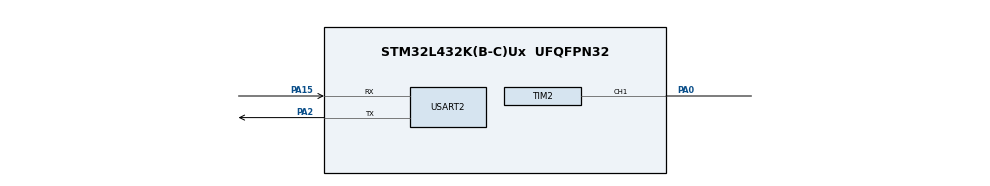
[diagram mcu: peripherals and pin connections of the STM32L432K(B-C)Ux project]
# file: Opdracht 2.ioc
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Mcu.Family=STM32L4
Mcu.Name=STM32L432K(B-C)Ux
Mcu.Package=UFQFPN32
NVIC.PriorityGroup=NVIC_PRIORITYGROUP_4
NVIC.TIM2_IRQn=true\:0\:0\:false\:false\:true\:true\:true\:true
NVIC.USART2_IRQn=true\:0\:0\:false\:false\:true\:true\:true\:true
PA0.GPIO_PuPd=GPIO_NOPULL
PA0.Signal=S_TIM2_CH1
PA15.Mode=Asynchronous
PA15.Signal=USART2_RX
PA13\ (JTMS-SWDIO).Mode=Serial_Wire
PA13\ (JTMS-SWDIO).Signal=SYS_JTMS-SWDIO
PA14\ (JTCK-SWCLK).Mode=Serial_Wire
PA14\ (JTCK-SWCLK).Signal=SYS_JTCK-SWCLK
PA2.Mode=Asynchronous
PA2.Signal=USART2_TX
ProjectManager.HeapSize=0x200
ProjectManager.StackSize=0x400
ProjectManager.TargetToolchain=MDK-ARM V5.32
RCC.HSE_VALUE=8000000
RCC.HSI48_VALUE=48000000
RCC.HSI_VALUE=16000000
RCC.LSE_VALUE=32768
RCC.MSI_VALUE=4000000
RCC.VCOOutputFreq_Value=32000000
SH.S_TIM2_CH1.0=TIM2_CH1,PWM Input on CH1
TIM2.Channel-PWM\ Input\ on\ CH1=TIM_CHANNEL_1
TIM2.Period=3699
TIM2.Prescaler=15
USART2.VirtualMode-Asynchronous=VM_ASYNC
board=custom

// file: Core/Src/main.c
/* USER CODE BEGIN Header */
/**
  ******************************************************************************
  * @file           : main.c
  * @brief          : Main program body
  ******************************************************************************
  * @attention
  *
  * Copyright (c) 2026 STMicroelectronics.
  * All rights reserved.
  *
  * This software is licensed under terms that can be found in the LICENSE file
  * in the root directory of this software component.
  * If no LICENSE file comes with this software, it is provided AS-IS.
  *
  ******************************************************************************
  */
/* USER CODE END Header */
#include "main.h"

/* USER CODE BEGIN Includes */

#include <stdio.h>

/* USER CODE END Includes */

/* USER CODE BEGIN PD */

#define RC5_HALF_MIN_US        640U
#define RC5_HALF_MAX_US        1140U
#define RC5_FULL_MIN_US        1340U
#define RC5_FULL_MAX_US        2220U
#define RC5_FRAME_BITS         14U
#define RC5_FRAME_HALFBITS     (RC5_FRAME_BITS * 2U)
#define RC5_BUFFER_HALFBITS    64U
/* Timing windows used to classify measured pulse widths into RC5 half/full bit times. */

/* USER CODE END PD */

TIM_HandleTypeDef htim2;

UART_HandleTypeDef huart2;

/* USER CODE BEGIN PV */

typedef struct
{
  uint16_t Raw;
  uint8_t StartBit;
  uint8_t FieldBit;
  uint8_t ToggleBit;
  uint8_t Address;
  uint8_t Command;
} IR_Frame_t;

volatile uint8_t RC5FrameReceived = RESET;
IR_Frame_t IR_FRAME;

static uint8_t rc5Collecting = 0U;
static uint8_t rc5HalfBits[RC5_BUFFER_HALFBITS];
static uint8_t rc5HalfCount = 0U;
/* Halfbit buffer stores logic levels after quantization for Manchester decoding. */

/* USER CODE END PV */

void SystemClock_Config(void);
static void MX_GPIO_Init(void);
static void MX_TIM2_Init(void);
static void MX_USART2_UART_Init(void);
/* USER CODE BEGIN PFP */

static void RC5_ResetState(void);
static uint8_t RC5_QuantizeHalfBits(uint32_t durationUs);
static void RC5_AppendLevel(uint8_t level, uint8_t count);
static void RC5_TryDecodeBuffer(void);
static void RC5_ProcessCapture(uint32_t periodUs, uint32_t lowUs);

/* USER CODE END PFP */

int main(void)
{

  /* MCU Configuration--------------------------------------------------------*/

  /* Reset of all peripherals, Initializes the Flash interface and the Systick. */
  HAL_Init();

  /* Configure the system clock */
  SystemClock_Config();

  /* Initialize all configured peripherals */
  MX_GPIO_Init();
  MX_TIM2_Init();
  MX_USART2_UART_Init();
  /* USER CODE BEGIN 2 */

  setvbuf(stdout, NULL, _IONBF, 0);

  RC5_ResetState();

  /* CH1 and CH2 captures are both needed: total period and low-time measurement. */
  if (HAL_TIM_IC_Start_IT(&htim2, TIM_CHANNEL_1) != HAL_OK)
  {
    Error_Handler();
  }
  if (HAL_TIM_IC_Start_IT(&htim2, TIM_CHANNEL_2) != HAL_OK)
  {
    Error_Handler();
  }
  if (HAL_TIM_Base_Start_IT(&htim2) != HAL_OK)
  {
    Error_Handler();
  }

  printf("RC5 receiver ready\r\n");

  /* USER CODE END 2 */

  /* Infinite loop */
  while (1)
  {

    /* USER CODE BEGIN 3 */
    /* Main loop only formats already-decoded data; decode work is done in interrupts. */
    if (RC5FrameReceived != RESET)
    {
      printf("[RC5] Raw: 0x%04X | Addr: 0x%02X | Cmd: 0x%02X | Toggle: %d\r\n",
             IR_FRAME.Raw,
             IR_FRAME.Address,
             IR_FRAME.Command,
             IR_FRAME.ToggleBit);
      RC5FrameReceived = RESET;
    }
  }
  /* USER CODE END 3 */
}

void SystemClock_Config(void)
{
  RCC_OscInitTypeDef RCC_OscInitStruct = {0};
  RCC_ClkInitTypeDef RCC_ClkInitStruct = {0};

  /** Configure the main internal regulator output voltage
  */
  if (HAL_PWREx_ControlVoltageScaling(PWR_REGULATOR_VOLTAGE_SCALE1) != HAL_OK)
  {
    Error_Handler();
  }

  /** Initializes the RCC Oscillators according to the specified parameters
  * in the RCC_OscInitTypeDef structure.
  */
  RCC_OscInitStruct.OscillatorType = RCC_OSCILLATORTYPE_MSI;
  RCC_OscInitStruct.MSIState = RCC_MSI_ON;
  RCC_OscInitStruct.MSICalibrationValue = 0;
  RCC_OscInitStruct.MSIClockRange = RCC_MSIRANGE_6;
  RCC_OscInitStruct.PLL.PLLState = RCC_PLL_NONE;
  if (HAL_RCC_OscConfig(&RCC_OscInitStruct) != HAL_OK)
  {
    Error_Handler();
  }

  /** Initializes the CPU, AHB and APB buses clocks
  */
  RCC_ClkInitStruct.ClockType = RCC_CLOCKTYPE_HCLK|RCC_CLOCKTYPE_SYSCLK
                              |RCC_CLOCKTYPE_PCLK1|RCC_CLOCKTYPE_PCLK2;
  RCC_ClkInitStruct.SYSCLKSource = RCC_SYSCLKSOURCE_MSI;
  RCC_ClkInitStruct.AHBCLKDivider = RCC_SYSCLK_DIV1;
  RCC_ClkInitStruct.APB1CLKDivider = RCC_HCLK_DIV1;
  RCC_ClkInitStruct.APB2CLKDivider = RCC_HCLK_DIV1;

  if (HAL_RCC_ClockConfig(&RCC_ClkInitStruct, FLASH_LATENCY_0) != HAL_OK)
  {
    Error_Handler();
  }
}

static void MX_TIM2_Init(void)
{

  TIM_SlaveConfigTypeDef sSlaveConfig = {0};
  TIM_MasterConfigTypeDef sMasterConfig = {0};
  TIM_IC_InitTypeDef sConfigIC = {0};

  htim2.Instance = TIM2;
  htim2.Init.Prescaler = 15;
  htim2.Init.CounterMode = TIM_COUNTERMODE_UP;
  htim2.Init.Period = 3699;
  htim2.Init.ClockDivision = TIM_CLOCKDIVISION_DIV1;
  htim2.Init.AutoReloadPreload = TIM_AUTORELOAD_PRELOAD_DISABLE;
  if (HAL_TIM_IC_Init(&htim2) != HAL_OK)
  {
    Error_Handler();
  }
  /* Reset mode: each selected trigger edge restarts the timer, giving segment timing. */
  sSlaveConfig.SlaveMode = TIM_SLAVEMODE_RESET;
  sSlaveConfig.InputTrigger = TIM_TS_TI1FP1;
  sSlaveConfig.TriggerPolarity = TIM_TRIGGERPOLARITY_FALLING;
  sSlaveConfig.TriggerFilter = 3;
  if (HAL_TIM_SlaveConfigSynchro(&htim2, &sSlaveConfig) != HAL_OK)
  {
    Error_Handler();
  }
  sMasterConfig.MasterOutputTrigger = TIM_TRGO_RESET;
  sMasterConfig.MasterSlaveMode = TIM_MASTERSLAVEMODE_DISABLE;
  if (HAL_TIMEx_MasterConfigSynchronization(&htim2, &sMasterConfig) != HAL_OK)
  {
    Error_Handler();
  }
  sConfigIC.ICPolarity = TIM_INPUTCHANNELPOLARITY_FALLING;
  sConfigIC.ICSelection = TIM_ICSELECTION_DIRECTTI;
  sConfigIC.ICPrescaler = TIM_ICPSC_DIV1;
  sConfigIC.ICFilter = 3;
  if (HAL_TIM_IC_ConfigChannel(&htim2, &sConfigIC, TIM_CHANNEL_1) != HAL_OK)
  {
    Error_Handler();
  }
  sConfigIC.ICPolarity = TIM_INPUTCHANNELPOLARITY_RISING;
  sConfigIC.ICSelection = TIM_ICSELECTION_INDIRECTTI;
  if (HAL_TIM_IC_ConfigChannel(&htim2, &sConfigIC, TIM_CHANNEL_2) != HAL_OK)
  {
    Error_Handler();
  }

}

static void MX_USART2_UART_Init(void)
{

  huart2.Instance = USART2;
  huart2.Init.BaudRate = 115200;
  huart2.Init.WordLength = UART_WORDLENGTH_8B;
  huart2.Init.StopBits = UART_STOPBITS_1;
  huart2.Init.Parity = UART_PARITY_NONE;
  huart2.Init.Mode = UART_MODE_TX_RX;
  huart2.Init.HwFlowCtl = UART_HWCONTROL_NONE;
  huart2.Init.OverSampling = UART_OVERSAMPLING_16;
  huart2.Init.OneBitSampling = UART_ONE_BIT_SAMPLE_DISABLE;
  huart2.AdvancedInit.AdvFeatureInit = UART_ADVFEATURE_NO_INIT;
  if (HAL_UART_Init(&huart2) != HAL_OK)
  {
    Error_Handler();
  }

}

static void MX_GPIO_Init(void)
{

  /* GPIO Ports Clock Enable */
  __HAL_RCC_GPIOA_CLK_ENABLE();

}

/* USER CODE BEGIN 4 */

int __io_putchar(int ch)
{
  /* Retarget printf single-character output to USART2. */
  HAL_UART_Transmit(&huart2, (uint8_t *)&ch, 1U, 100U);
  return ch;
}

int _write(int file, char *ptr, int len)
{
  (void)file;
  /* Retarget libc buffered writes (printf strings) to USART2. */
  HAL_UART_Transmit(&huart2, (uint8_t *)ptr, (uint16_t)len, HAL_MAX_DELAY);
  return len;
}

void HAL_TIM_IC_CaptureCallback(TIM_HandleTypeDef *htim)
{
  if ((htim->Instance == TIM2) && (htim->Channel == HAL_TIM_ACTIVE_CHANNEL_1))
  {
    /* CH1 captures segment period, CH2 captures low portion of the same segment. */
    uint32_t periodUs = HAL_TIM_ReadCapturedValue(htim, TIM_CHANNEL_1);
    uint32_t lowUs = HAL_TIM_ReadCapturedValue(htim, TIM_CHANNEL_2);
    RC5_ProcessCapture(periodUs, lowUs);
  }
}

void HAL_TIM_PeriodElapsedCallback(TIM_HandleTypeDef *htim)
{
  if (htim->Instance == TIM2)
  {
    /* Timeout means stream likely ended; clear partial decode state. */
    if (RC5FrameReceived == RESET)
    {
      RC5_ResetState();
    }
  }
}

static void RC5_ResetState(void)
{
  /* Keep function tiny: reset only state machine variables. */
  rc5Collecting = 0U;
  rc5HalfCount = 0U;
}

static uint8_t RC5_QuantizeHalfBits(uint32_t durationUs)
{
  /* Map measured segment durations to 1 or 2 halfbits, else invalid (0). */
  if ((durationUs >= RC5_HALF_MIN_US) && (durationUs <= RC5_HALF_MAX_US))
  {
    return 1U;
  }
  if ((durationUs >= RC5_FULL_MIN_US) && (durationUs <= RC5_FULL_MAX_US))
  {
    return 2U;
  }
  return 0U;
}

static void RC5_AppendLevel(uint8_t level, uint8_t count)
{
  /* Push repeated logic level into the halfbit stream buffer. */
  while ((count > 0U) && (rc5HalfCount < RC5_BUFFER_HALFBITS))
  {
    rc5HalfBits[rc5HalfCount++] = level;
    count--;
  }
}

static void RC5_TryDecodeBuffer(void)
{
  uint8_t offset;

  /* Try small phase offsets because capture can start at different halfbit alignments. */
  for (offset = 0U; (offset < 3U) && ((offset + RC5_FRAME_HALFBITS) <= rc5HalfCount); offset++)
  {
    uint8_t i;
    uint16_t raw = 0U;
    uint8_t valid = 1U;

    for (i = 0U; i < RC5_FRAME_BITS; i++)
    {
      uint8_t firstHalf = rc5HalfBits[offset + (2U * i)];
      uint8_t secondHalf = rc5HalfBits[offset + (2U * i) + 1U];

      /* Manchester decode: 10 -> bit 1, 01 -> bit 0, all else invalid. */
      if ((firstHalf == 1U) && (secondHalf == 0U))
      {
        raw = (uint16_t)((raw << 1) | 1U);
      }
      else if ((firstHalf == 0U) && (secondHalf == 1U))
      {
        raw = (uint16_t)(raw << 1);
      }
      else
      {
        valid = 0U;
        break;
      }
    }

    if ((valid != 0U) && (((raw >> 13) & 0x01U) == 1U) && (((raw >> 12) & 0x01U) == 1U))
    {
      uint8_t fieldBit = (uint8_t)((raw >> 12) & 0x01U);
      uint8_t command = (uint8_t)(raw & 0x3FU);

      /* RC5 extended command set: field bit extends command MSB when zero. */
      if (fieldBit == 0U)
      {
        command |= 0x40U;
      }

      IR_FRAME.Raw = raw;
      IR_FRAME.StartBit = (uint8_t)((raw >> 13) & 0x01U);
      IR_FRAME.FieldBit = fieldBit;
      IR_FRAME.ToggleBit = (uint8_t)((raw >> 11) & 0x01U);
      IR_FRAME.Address = (uint8_t)((raw >> 6) & 0x1FU);
      IR_FRAME.Command = command;
      RC5FrameReceived = SET;

      RC5_ResetState();
      return;
    }
  }

  if (rc5HalfCount > 40U)
  {
    /* Keep a trailing window to continue decoding across frame boundary/noise. */
    uint8_t keep = 28U;
    uint8_t i;
    for (i = 0U; i < keep; i++)
    {
      rc5HalfBits[i] = rc5HalfBits[rc5HalfCount - keep + i];
    }
    rc5HalfCount = keep;
  }
}

static void RC5_ProcessCapture(uint32_t periodUs, uint32_t lowUs)
{
  uint8_t lowHalfCount;
  uint8_t highHalfCount;
  uint32_t highUs;

  if ((periodUs == 0U) || (lowUs == 0U) || (lowUs >= periodUs))
  {
    /* Reject malformed captures early. */
    RC5_ResetState();
    return;
  }

  if (rc5Collecting == 0U)
  {
    /* First valid capture starts a new stream; prepend idle-high halfbit. */
    rc5Collecting = 1U;
    rc5HalfCount = 0U;
    RC5_AppendLevel(1U, 1U);
  }

  highUs = periodUs - lowUs;
  lowHalfCount = RC5_QuantizeHalfBits(lowUs);
  highHalfCount = RC5_QuantizeHalfBits(highUs);

  if ((lowHalfCount == 0U) || (highHalfCount == 0U))
  {
    /* If one segment is out of timing window, restart decoder state machine. */
    RC5_ResetState();
    return;
  }

  RC5_AppendLevel(0U, lowHalfCount);
  RC5_AppendLevel(1U, highHalfCount);

  if (rc5HalfCount >= RC5_FRAME_HALFBITS)
  {
    /* Attempt decode whenever at least one full RC5 frame worth of halfbits exists. */
    RC5_TryDecodeBuffer();
  }
}

/* USER CODE END 4 */

void Error_Handler(void)
{
  __disable_irq();
  while (1)
  {
  }
}
